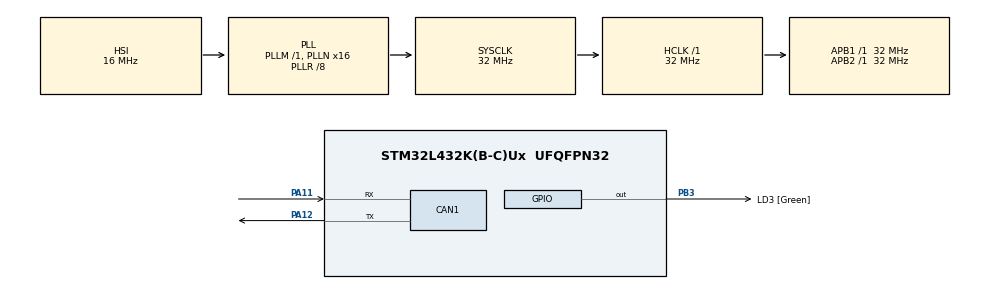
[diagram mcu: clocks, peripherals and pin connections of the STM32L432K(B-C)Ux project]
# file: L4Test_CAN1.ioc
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CAN1.BS1=CAN_BS1_2TQ
CAN1.BS2=CAN_BS2_1TQ
CAN1.CalculateTimeBit=2000
CAN1.CalculateTimeQuantum=500.0
FREERTOS.Tasks01=defaultTask,0,128,StartDefaultTask,Default,NULL
Mcu.Family=STM32L4
Mcu.Name=STM32L432K(B-C)Ux
Mcu.Package=UFQFPN32
NVIC.PriorityGroup=NVIC_PRIORITYGROUP_4
NVIC.TIM1_UP_TIM16_IRQn=true\:0\:0\:false\:false\:true\:false
NVIC.TimeBase=TIM1_UP_TIM16_IRQn
NVIC.TimeBaseIP=TIM1
PA0.GPIO_Label=MCO [High speed clock in]
PA0.Signal=RCC_CK_IN
PA11.Mode=Master
PA11.Signal=CAN1_RX
PA12.Mode=Master
PA12.Signal=CAN1_TX
PA13\ (JTMS-SWDIO).GPIO_Label=SWDIO
PA13\ (JTMS-SWDIO).Mode=Serial_Wire
PA13\ (JTMS-SWDIO).Signal=SYS_JTMS-SWDIO
PA14\ (JTCK-SWCLK).GPIO_Label=SWCLK
PA14\ (JTCK-SWCLK).Mode=Serial_Wire
PA14\ (JTCK-SWCLK).Signal=SYS_JTCK-SWCLK
PA15\ (JTDI).GPIO_Label=VCP_RX
PA15\ (JTDI).Signal=USART2_RX
PA2.GPIO_Label=VCP_TX
PA2.Signal=USART2_TX
PB3\ (JTDO-TRACESWO).GPIO_Label=LD3 [Green]
PB3\ (JTDO-TRACESWO).Signal=GPIO_Output
PC14-OSC32_IN\ (PC14).Signal=RCC_OSC32_IN
PC15-OSC32_OUT\ (PC15).Signal=RCC_OSC32_OUT
ProjectManager.HeapSize=0x200
ProjectManager.StackSize=0x400
ProjectManager.TargetToolchain=SW4STM32
RCC.ADCFreq_Value=64000000
RCC.AHBFreq_Value=32000000
RCC.APB1Freq_Value=32000000
RCC.APB1TimFreq_Value=32000000
RCC.APB2Freq_Value=32000000
RCC.APB2TimFreq_Value=32000000
RCC.CortexFreq_Value=32000000
RCC.HCLKFreq_Value=32000000
RCC.HSI16_VALUE=16000000
RCC.HSI48_VALUE=48000000
RCC.HSI_VALUE=16000000
RCC.MSI_VALUE=4000000
RCC.PLLMUL=RCC_PLLMUL_4
RCC.PLLN=16
RCC.PLLR=RCC_PLLR_DIV8
RCC.PLLSourceVirtual=RCC_PLLSOURCE_HSI
RCC.SYSCLKFreq_VALUE=32000000
RCC.SYSCLKSource=RCC_SYSCLKSOURCE_PLLCLK
RCC.USBFreq_Value=64000000
RCC.VCOOutputFreq_Value=256000000
VP_FREERTOS_VS_ENABLE.Mode=Enabled
VP_RTC_VS_RTC_Activate.Mode=RTC_Enabled
VP_SYS_VS_tim1.Mode=TIM1
board=NUCLEO-L432KC

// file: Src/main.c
/**
  ******************************************************************************
  * File Name          : main.c
  * Description        : Main program body
  ******************************************************************************
  * This notice applies to any and all portions of this file
  * that are not between comment pairs USER CODE BEGIN and
  * USER CODE END. Other portions of this file, whether
  * inserted by the user or by software development tools
  * are owned by their respective copyright owners.
  *
  * Copyright (c) 2018 STMicroelectronics International N.V.
  * All rights reserved.
  *
  * Redistribution and use in source and binary forms, with or without
  * modification, are permitted, provided that the following conditions are met:
  *
  * 1. Redistribution of source code must retain the above copyright notice,
  *    this list of conditions and the following disclaimer.
  * 2. Redistributions in binary form must reproduce the above copyright notice,
  *    this list of conditions and the following disclaimer in the documentation
  *    and/or other materials provided with the distribution.
  * 3. Neither the name of STMicroelectronics nor the names of other
  *    contributors to this software may be used to endorse or promote products
  *    derived from this software without specific written permission.
  * 4. This software, including modifications and/or derivative works of this
  *    software, must execute solely and exclusively on microcontroller or
  *    microprocessor devices manufactured by or for STMicroelectronics.
  * 5. Redistribution and use of this software other than as permitted under
  *    this license is void and will automatically terminate your rights under
  *    this license.
  *
  * THIS SOFTWARE IS PROVIDED BY STMICROELECTRONICS AND CONTRIBUTORS "AS IS"
  * AND ANY EXPRESS, IMPLIED OR STATUTORY WARRANTIES, INCLUDING, BUT NOT
  * LIMITED TO, THE IMPLIED WARRANTIES OF MERCHANTABILITY, FITNESS FOR A
  * PARTICULAR PURPOSE AND NON-INFRINGEMENT OF THIRD PARTY INTELLECTUAL PROPERTY
  * RIGHTS ARE DISCLAIMED TO THE FULLEST EXTENT PERMITTED BY LAW. IN NO EVENT
  * SHALL STMICROELECTRONICS OR CONTRIBUTORS BE LIABLE FOR ANY DIRECT, INDIRECT,
  * INCIDENTAL, SPECIAL, EXEMPLARY, OR CONSEQUENTIAL DAMAGES (INCLUDING, BUT NOT
  * LIMITED TO, PROCUREMENT OF SUBSTITUTE GOODS OR SERVICES; LOSS OF USE, DATA,
  * OR PROFITS; OR BUSINESS INTERRUPTION) HOWEVER CAUSED AND ON ANY THEORY OF
  * LIABILITY, WHETHER IN CONTRACT, STRICT LIABILITY, OR TORT (INCLUDING
  * NEGLIGENCE OR OTHERWISE) ARISING IN ANY WAY OUT OF THE USE OF THIS SOFTWARE,
  * EVEN IF ADVISED OF THE POSSIBILITY OF SUCH DAMAGE.
  *
  ******************************************************************************
  */
#include "main.h"
#include "stm32l4xx_hal.h"
#include "cmsis_os.h"

CAN_HandleTypeDef hcan1;

RTC_HandleTypeDef hrtc;

osThreadId defaultTaskHandle;

/* USER CODE BEGIN PV */
/* Private variables ---------------------------------------------------------*/

/* USER CODE END PV */

void SystemClock_Config(void);
static void MX_GPIO_Init(void);
static void MX_CAN1_Init(void);
static void MX_RTC_Init(void);
void StartDefaultTask(void const * argument);

/* USER CODE BEGIN PFP */
/* Private function prototypes -----------------------------------------------*/

/* USER CODE END PFP */

/* USER CODE BEGIN 0 */
void taskBlink(void* can)
{
	//vTaskDelay(5000); //TESTING1
	while (1)
	{
		//HAL_GPIO_TogglePin(FRG_RUN_CTRL_GPIO_Port, FRG_RUN_CTRL_Pin);
		HAL_GPIO_TogglePin(LD3_GPIO_Port, LD3_Pin);
		//HAL_GPIO_TogglePin(LD5_GPIO_Port, LD5_Pin);

		CanTxMsgTypeDef tx;

		tx.IDE = CAN_ID_STD;
		tx.RTR = CAN_RTR_DATA;
		tx.StdId = 0x200;
		tx.DLC = 1;
		tx.Data[0] = 0xab;
//		if (car.state == CAR_STATE_INIT)
//		{
//			tx.Data[0] = 0;
//		}
//		else if (car.state == CAR_STATE_READY2DRIVE)
//		{
//			tx.Data[0] = 1;
//		}
//		//req regid 40

		hcan1.pTxMsg = &tx;
		HAL_CAN_Transmit(&hcan1, 1000);						//transmit staged message

//
//		xQueueSendToBack(car.q_txcan, &tx, 100);
		//mcCmdTransmissionRequestSingle(0x40);
		vTaskDelay(255);
	}
}
/* USER CODE END 0 */

int main(void)
{

  /* MCU Configuration----------------------------------------------------------*/

  /* Reset of all peripherals, Initializes the Flash interface and the Systick. */
  HAL_Init();

  /* Configure the system clock */
  SystemClock_Config();

  /* Initialize all configured peripherals */
  MX_GPIO_Init();
  MX_CAN1_Init();
  MX_RTC_Init();

  /* USER CODE BEGIN 2 */
	xTaskCreate(taskBlink, "blink", 256, NULL, 1, NULL);

  /* USER CODE END 2 */

  /* Create the thread(s) */
  /* definition and creation of defaultTask */
  osThreadDef(defaultTask, StartDefaultTask, osPriorityNormal, 0, 128);
  defaultTaskHandle = osThreadCreate(osThread(defaultTask), NULL);

  /* Start scheduler */
  osKernelStart();

  /* We should never get here as control is now taken by the scheduler */

  /* Infinite loop */
  while (1)
  {

  }

}

/** System Clock Configuration
*/
void SystemClock_Config(void)
{

  RCC_OscInitTypeDef RCC_OscInitStruct;
  RCC_ClkInitTypeDef RCC_ClkInitStruct;
  RCC_PeriphCLKInitTypeDef PeriphClkInit;

    /**Initializes the CPU, AHB and APB busses clocks
    */
  RCC_OscInitStruct.OscillatorType = RCC_OSCILLATORTYPE_HSI|RCC_OSCILLATORTYPE_LSI;
  RCC_OscInitStruct.HSIState = RCC_HSI_ON;
  RCC_OscInitStruct.HSICalibrationValue = 16;
  RCC_OscInitStruct.LSIState = RCC_LSI_ON;
  RCC_OscInitStruct.PLL.PLLState = RCC_PLL_ON;
  RCC_OscInitStruct.PLL.PLLSource = RCC_PLLSOURCE_HSI;
  RCC_OscInitStruct.PLL.PLLM = 1;
  RCC_OscInitStruct.PLL.PLLN = 16;
  RCC_OscInitStruct.PLL.PLLP = RCC_PLLP_DIV7;
  RCC_OscInitStruct.PLL.PLLQ = RCC_PLLQ_DIV2;
  RCC_OscInitStruct.PLL.PLLR = RCC_PLLR_DIV8;
  if (HAL_RCC_OscConfig(&RCC_OscInitStruct) != HAL_OK)
  {
    _Error_Handler(__FILE__, __LINE__);
  }

    /**Initializes the CPU, AHB and APB busses clocks
    */
  RCC_ClkInitStruct.ClockType = RCC_CLOCKTYPE_HCLK|RCC_CLOCKTYPE_SYSCLK
                              |RCC_CLOCKTYPE_PCLK1|RCC_CLOCKTYPE_PCLK2;
  RCC_ClkInitStruct.SYSCLKSource = RCC_SYSCLKSOURCE_PLLCLK;
  RCC_ClkInitStruct.AHBCLKDivider = RCC_SYSCLK_DIV1;
  RCC_ClkInitStruct.APB1CLKDivider = RCC_HCLK_DIV1;
  RCC_ClkInitStruct.APB2CLKDivider = RCC_HCLK_DIV1;

  if (HAL_RCC_ClockConfig(&RCC_ClkInitStruct, FLASH_LATENCY_1) != HAL_OK)
  {
    _Error_Handler(__FILE__, __LINE__);
  }

  PeriphClkInit.PeriphClockSelection = RCC_PERIPHCLK_RTC;
  PeriphClkInit.RTCClockSelection = RCC_RTCCLKSOURCE_LSI;
  if (HAL_RCCEx_PeriphCLKConfig(&PeriphClkInit) != HAL_OK)
  {
    _Error_Handler(__FILE__, __LINE__);
  }

    /**Configure the main internal regulator output voltage
    */
  if (HAL_PWREx_ControlVoltageScaling(PWR_REGULATOR_VOLTAGE_SCALE1) != HAL_OK)
  {
    _Error_Handler(__FILE__, __LINE__);
  }

    /**Configure the Systick interrupt time
    */
  HAL_SYSTICK_Config(HAL_RCC_GetHCLKFreq()/1000);

    /**Configure the Systick
    */
  HAL_SYSTICK_CLKSourceConfig(SYSTICK_CLKSOURCE_HCLK);

  /* SysTick_IRQn interrupt configuration */
  HAL_NVIC_SetPriority(SysTick_IRQn, 15, 0);
}

/* CAN1 init function */
static void MX_CAN1_Init(void)
{

  hcan1.Instance = CAN1;
  hcan1.Init.Prescaler = 16;
  hcan1.Init.Mode = CAN_MODE_NORMAL;
  hcan1.Init.SJW = CAN_SJW_1TQ;
  hcan1.Init.BS1 = CAN_BS1_2TQ;
  hcan1.Init.BS2 = CAN_BS2_1TQ;
  hcan1.Init.TTCM = DISABLE;
  hcan1.Init.ABOM = DISABLE;
  hcan1.Init.AWUM = DISABLE;
  hcan1.Init.NART = DISABLE;
  hcan1.Init.RFLM = DISABLE;
  hcan1.Init.TXFP = DISABLE;
  if (HAL_CAN_Init(&hcan1) != HAL_OK)
  {
    _Error_Handler(__FILE__, __LINE__);
  }

}

/* RTC init function */
static void MX_RTC_Init(void)
{

    /**Initialize RTC Only
    */
  hrtc.Instance = RTC;
  hrtc.Init.HourFormat = RTC_HOURFORMAT_24;
  hrtc.Init.AsynchPrediv = 127;
  hrtc.Init.SynchPrediv = 255;
  hrtc.Init.OutPut = RTC_OUTPUT_DISABLE;
  hrtc.Init.OutPutRemap = RTC_OUTPUT_REMAP_NONE;
  hrtc.Init.OutPutPolarity = RTC_OUTPUT_POLARITY_HIGH;
  hrtc.Init.OutPutType = RTC_OUTPUT_TYPE_OPENDRAIN;
  if (HAL_RTC_Init(&hrtc) != HAL_OK)
  {
    _Error_Handler(__FILE__, __LINE__);
  }

}

/** Configure pins as
        * Analog
        * Input
        * Output
        * EVENT_OUT
        * EXTI
     PA2   ------> USART2_TX
     PA15 (JTDI)   ------> USART2_RX
*/
static void MX_GPIO_Init(void)
{

  GPIO_InitTypeDef GPIO_InitStruct;

  /* GPIO Ports Clock Enable */
  __HAL_RCC_GPIOC_CLK_ENABLE();
  __HAL_RCC_GPIOA_CLK_ENABLE();
  __HAL_RCC_GPIOB_CLK_ENABLE();

  /*Configure GPIO pin Output Level */
  HAL_GPIO_WritePin(LD3_GPIO_Port, LD3_Pin, GPIO_PIN_RESET);

  /*Configure GPIO pin : VCP_TX_Pin */
  GPIO_InitStruct.Pin = VCP_TX_Pin;
  GPIO_InitStruct.Mode = GPIO_MODE_AF_PP;
  GPIO_InitStruct.Pull = GPIO_NOPULL;
  GPIO_InitStruct.Speed = GPIO_SPEED_FREQ_VERY_HIGH;
  GPIO_InitStruct.Alternate = GPIO_AF7_USART2;
  HAL_GPIO_Init(VCP_TX_GPIO_Port, &GPIO_InitStruct);

  /*Configure GPIO pin : VCP_RX_Pin */
  GPIO_InitStruct.Pin = VCP_RX_Pin;
  GPIO_InitStruct.Mode = GPIO_MODE_AF_PP;
  GPIO_InitStruct.Pull = GPIO_NOPULL;
  GPIO_InitStruct.Speed = GPIO_SPEED_FREQ_VERY_HIGH;
  GPIO_InitStruct.Alternate = GPIO_AF3_USART2;
  HAL_GPIO_Init(VCP_RX_GPIO_Port, &GPIO_InitStruct);

  /*Configure GPIO pin : LD3_Pin */
  GPIO_InitStruct.Pin = LD3_Pin;
  GPIO_InitStruct.Mode = GPIO_MODE_OUTPUT_PP;
  GPIO_InitStruct.Pull = GPIO_NOPULL;
  GPIO_InitStruct.Speed = GPIO_SPEED_FREQ_LOW;
  HAL_GPIO_Init(LD3_GPIO_Port, &GPIO_InitStruct);

}

/* StartDefaultTask function */
void StartDefaultTask(void const * argument)
{

  for(;;)
  {
    osDelay(1);
  }
}

void HAL_TIM_PeriodElapsedCallback(TIM_HandleTypeDef *htim)
{
  if (htim->Instance == TIM1) {
    HAL_IncTick();
  }
}

void _Error_Handler(char * file, int line)
{
  while(1)
  {
  }
}

/************************ (C) COPYRIGHT STMicroelectronics *****END OF FILE****/
